# f28003x_sys_status_regs register map
Vendor: Texas Instruments
Peripheral module from a debugger description file (folder C2000).
Address unit: 16 bits
Registers are 32-bit, read-write, no defined reset value unless marked. A register's access mark holds for its fields unless they carry their own. Offsets are as the file gives them; lines under a group give offsets from that group; [hi:lo] are bit positions; {n}, {i} and the like mark numbered series; 'fields as' and 'values as' point back to an identical list; <NAME> marks a mode.

## SYS_STATUS_REGS — SYS STATUS Registers
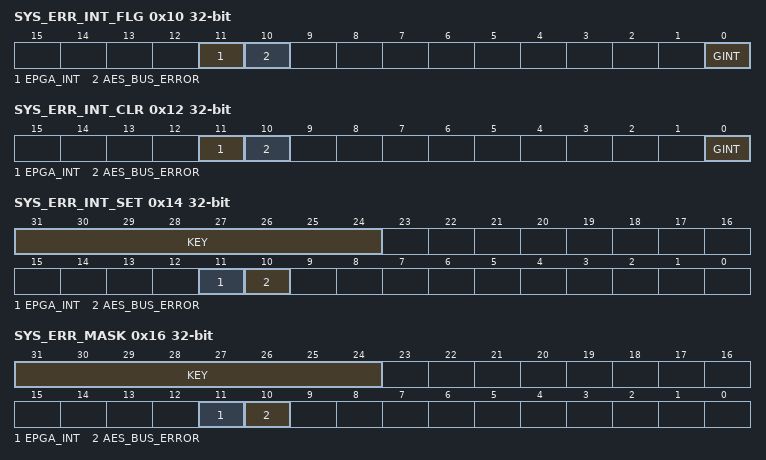
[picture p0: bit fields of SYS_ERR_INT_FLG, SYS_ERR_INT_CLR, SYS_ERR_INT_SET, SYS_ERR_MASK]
0x10 SYS_ERR_INT_FLG ro — Status of interrupts due to multiple different errors in the system.
  [11] EPGA_INT — EPGA_INT Interrupt flag.
  [10] AES_BUS_ERROR — AES_BUS_ERROR Interrupt flag.
  [0] GINT — Global Interrupt flag
0x12 SYS_ERR_INT_CLR — SYS_ERR_INT_FLG clear register
  [11] EPGA_INT — EPGA_INT interrupt flag clear bit
  [10] AES_BUS_ERROR — AES_BUS_ERROR interrupt flag clear bit
  [0] GINT — Global Interrupt flag Clear bit
0x14 SYS_ERR_INT_SET — SYS_ERR_INT_FLG set register
  [31:24] KEY
  [11] EPGA_INT — EPGA_INT interrupt flag set bit
  [10] AES_BUS_ERROR — AES_BUS_ERROR interrupt flag set bit
0x16 SYS_ERR_MASK
  [31:24] KEY
  [11] EPGA_INT — EPGA_INT flag mask bit
  [10] AES_BUS_ERROR — AES_BUS_ERROR flag mask bit
